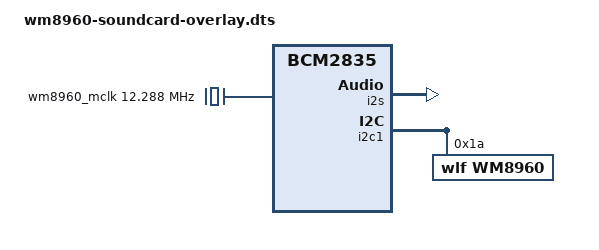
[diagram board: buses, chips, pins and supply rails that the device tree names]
/dts-v1/;
/plugin/;

/ {
	compatible = "brcm,bcm2835";

	fragment@0 {
		target = <&i2s>;
		__overlay__ {
			status = "okay";
		};
	};

	fragment@1 {
		target = <&i2c1>;
		__overlay__ {
			#address-cells = <1>;
			#size-cells = <0>;
			status = "okay";

			wm8960: wm8960@1a {
				compatible = "wlf,wm8960";
				reg = <0x1a>;
				#sound-dai-cells = <0>;
				wlf,shared-lrclk;
			};
		};
	};

	fragment@2 {
		target-path = "/";
		__overlay__ {
			wm8960_mclk: wm8960_mclk {
				compatible = "fixed-clock";
				#clock-cells = <0>;
				clock-frequency = <12288000>;
			};
		};
	};

	fragment@3 {
		target-path = "/";
		__overlay__ {
			sound {
				compatible = "wm8960-soundcard";
				i2s-controller = <&i2s>;
				audio-codec = <&wm8960>;
				status = "okay";
			};
		};
	};

	__overrides__ {
		alsaname = <&wm8960_soundcard>,"wm8960-soundcard,name";
	};
};
